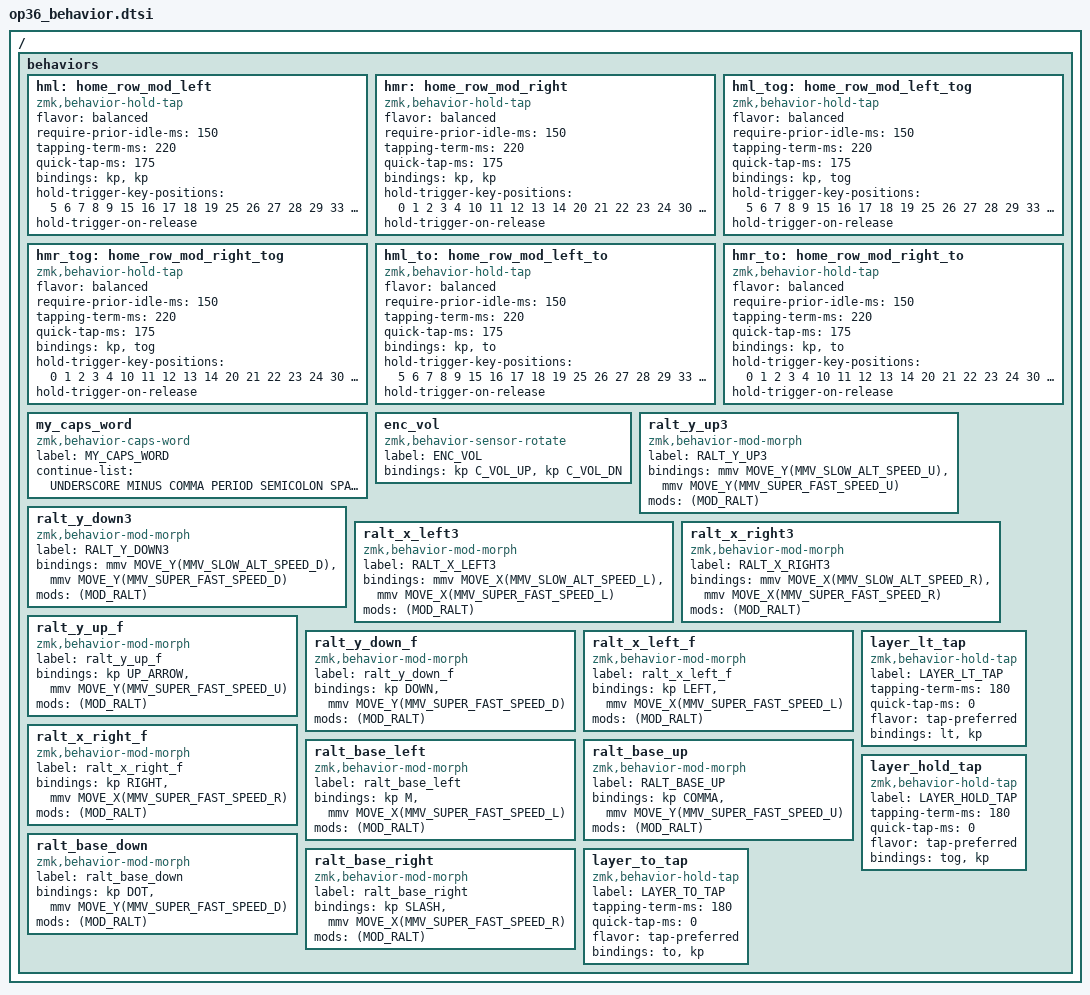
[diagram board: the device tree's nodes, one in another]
// op36_behavior.dtsi

#include "op36_const.dtsi"

/ {
    behaviors {
        hml: home_row_mod_left {
            compatible = "zmk,behavior-hold-tap";
            #binding-cells = <2>;
            flavor = "balanced";
            require-prior-idle-ms = <150>;
            tapping-term-ms = <220>;
            quick-tap-ms = <175>;
            bindings = <&kp>, <&kp>;

            hold-trigger-key-positions = <5 6 7 8 9 15 16 17 18 19 25 26 27 28 29 33 34 35>;
            hold-trigger-on-release;
        };

        hmr: home_row_mod_right {
            compatible = "zmk,behavior-hold-tap";
            #binding-cells = <2>;
            flavor = "balanced";
            require-prior-idle-ms = <150>;
            tapping-term-ms = <220>;
            quick-tap-ms = <175>;
            bindings = <&kp>, <&kp>;

            hold-trigger-key-positions = <0 1 2 3 4 10 11 12 13 14 20 21 22 23 24 30 31 32>;
            hold-trigger-on-release;
        };
        
hml_tog: home_row_mod_left_tog {
            compatible = "zmk,behavior-hold-tap";
            #binding-cells = <2>;
            flavor = "balanced";
            require-prior-idle-ms = <150>;
            tapping-term-ms = <220>;
            quick-tap-ms = <175>;
            bindings = <&kp>, <&tog>;

            hold-trigger-key-positions = <5 6 7 8 9 15 16 17 18 19 25 26 27 28 29 33 34 35>;
            hold-trigger-on-release;
        };

        hmr_tog: home_row_mod_right_tog {
            compatible = "zmk,behavior-hold-tap";
            #binding-cells = <2>;
            flavor = "balanced";
            require-prior-idle-ms = <150>;
            tapping-term-ms = <220>;
            quick-tap-ms = <175>;
            bindings = <&kp>, <&tog>;

            hold-trigger-key-positions = <0 1 2 3 4 10 11 12 13 14 20 21 22 23 24 30 31 32>;
            hold-trigger-on-release;
        };
        
        hml_to: home_row_mod_left_to {
                    compatible = "zmk,behavior-hold-tap";
                    #binding-cells = <2>;
                    flavor = "balanced";
                    require-prior-idle-ms = <150>;
                    tapping-term-ms = <220>;
                    quick-tap-ms = <175>;
                    bindings = <&kp>, <&to>;
        
                    hold-trigger-key-positions = <5 6 7 8 9 15 16 17 18 19 25 26 27 28 29 33 34 35>;
                    hold-trigger-on-release;
                };
        
                hmr_to: home_row_mod_right_to {
                    compatible = "zmk,behavior-hold-tap";
                    #binding-cells = <2>;
                    flavor = "balanced";
                    require-prior-idle-ms = <150>;
                    tapping-term-ms = <220>;
                    quick-tap-ms = <175>;
                    bindings = <&kp>, <&to>;
        
                    hold-trigger-key-positions = <0 1 2 3 4 10 11 12 13 14 20 21 22 23 24 30 31 32>;
                    hold-trigger-on-release;
                };                
        
         my_caps_word: my_caps_word {
             compatible = "zmk,behavior-caps-word";
             label = "MY_CAPS_WORD";
             #binding-cells = <0>;
             continue-list = <UNDERSCORE MINUS COMMA PERIOD SEMICOLON SPACE SLASH BACKSLASH>;
         };
                    
            enc_vol: enc_vol {
              compatible = "zmk,behavior-sensor-rotate";
              label = "ENC_VOL";
              #sensor-binding-cells = <0>;
              bindings = <&kp C_VOL_UP>, <&kp C_VOL_DN>;
            };
            
            ralt_y_up3: ralt_y_up3 {
              compatible = "zmk,behavior-mod-morph";
              label = "RALT_Y_UP3";
              #binding-cells = <0>;
              bindings = 
                <&mmv MOVE_Y(MMV_SLOW_ALT_SPEED_U)>,
                <&mmv MOVE_Y(MMV_SUPER_FAST_SPEED_U)>;
              mods = <(MOD_RALT)>;
            };
        
            ralt_y_down3: ralt_y_down3 {
              compatible = "zmk,behavior-mod-morph";
              label = "RALT_Y_DOWN3";
              #binding-cells = <0>;
              bindings = 
                <&mmv MOVE_Y(MMV_SLOW_ALT_SPEED_D)>,
                <&mmv MOVE_Y(MMV_SUPER_FAST_SPEED_D)>;
              mods = <(MOD_RALT)>;
            };
        
            ralt_x_left3: ralt_x_left3 {
              compatible = "zmk,behavior-mod-morph";
              label = "RALT_X_LEFT3";
              #binding-cells = <0>;
              bindings =
                <&mmv MOVE_X(MMV_SLOW_ALT_SPEED_L)>,
                <&mmv MOVE_X(MMV_SUPER_FAST_SPEED_L)>;
              mods = <(MOD_RALT)>;
            };
        
            ralt_x_right3: ralt_x_right3 {
              compatible = "zmk,behavior-mod-morph";
              label = "RALT_X_RIGHT3";
              #binding-cells = <0>;
              bindings =
                <&mmv MOVE_X(MMV_SLOW_ALT_SPEED_R)>,
                <&mmv MOVE_X(MMV_SUPER_FAST_SPEED_R)>;
              mods = <(MOD_RALT)>;
            };
            
            /* */
            ralt_y_up_f: ralt_y_up_f {
                  compatible = "zmk,behavior-mod-morph";
                  label = "ralt_y_up_f";
                  #binding-cells = <0>;
                  bindings = 
                    <&kp UP_ARROW>,
                    <&mmv MOVE_Y(MMV_SUPER_FAST_SPEED_U)>;
                  mods = <(MOD_RALT)>;
                };
            
                ralt_y_down_f: ralt_y_down_f {
                  compatible = "zmk,behavior-mod-morph";
                  label = "ralt_y_down_f";
                  #binding-cells = <0>;
                  bindings = 
                    <&kp DOWN>,
                    <&mmv MOVE_Y(MMV_SUPER_FAST_SPEED_D)>;
                  mods = <(MOD_RALT)>;
                };
            
                ralt_x_left_f: ralt_x_left_f {
                  compatible = "zmk,behavior-mod-morph";
                  label = "ralt_x_left_f";
                  #binding-cells = <0>;
                  bindings =
                    <&kp LEFT>,
                    <&mmv MOVE_X(MMV_SUPER_FAST_SPEED_L)>;
                  mods = <(MOD_RALT)>;
                };
            
                ralt_x_right_f: ralt_x_right_f {
                  compatible = "zmk,behavior-mod-morph";
                  label = "ralt_x_right_f";
                  #binding-cells = <0>;
                  bindings =
                    <&kp RIGHT>,
                    <&mmv MOVE_X(MMV_SUPER_FAST_SPEED_R)>;
                  mods = <(MOD_RALT)>;
                };
            /* */
        
            /* mouse 0 layer */
            ralt_base_left: ralt_base_left {
              compatible = "zmk,behavior-mod-morph";
              label = "ralt_base_left";
              #binding-cells = <0>;
              bindings =
                <&kp M>,
                <&mmv MOVE_X(MMV_SUPER_FAST_SPEED_L)>;
              mods = <(MOD_RALT)>;
            };
        
            ralt_base_up: ralt_base_up {
              compatible = "zmk,behavior-mod-morph";
              label = "RALT_BASE_UP";
              #binding-cells = <0>;
              bindings = 
                <&kp COMMA>,
                <&mmv MOVE_Y(MMV_SUPER_FAST_SPEED_U)>;
              mods = <(MOD_RALT)>;
            };
        
            ralt_base_down: ralt_base_down {
              compatible = "zmk,behavior-mod-morph";
              label = "ralt_base_down";
              #binding-cells = <0>;
              bindings = 
                <&kp DOT>,
                <&mmv MOVE_Y(MMV_SUPER_FAST_SPEED_D)>;
              mods = <(MOD_RALT)>;
            };
        
            ralt_base_right: ralt_base_right {
              compatible = "zmk,behavior-mod-morph";
              label = "ralt_base_right";
              #binding-cells = <0>;
              bindings =
                <&kp SLASH>,
                <&mmv MOVE_X(MMV_SUPER_FAST_SPEED_R)>;
              mods = <(MOD_RALT)>;
            };
            /* end mouse 0 layer */
        
            layer_lt_tap: layer_lt_tap {
              compatible = "zmk,behavior-hold-tap";
              label = "LAYER_LT_TAP";
              #binding-cells = <2>;
              tapping-term-ms = <180>;
              quick-tap-ms = <0>;
              flavor = "tap-preferred";
              bindings = <&lt>, <&kp>;
            };
        
            layer_hold_tap: layer_hold_tap {
              compatible = "zmk,behavior-hold-tap";
              label = "LAYER_HOLD_TAP";
              #binding-cells = <2>;
              tapping-term-ms = <180>;
              quick-tap-ms = <0>;
              flavor = "tap-preferred";
              bindings = <&tog>, <&kp>;
            };
            
            layer_to_tap: layer_to_tap {
              compatible = "zmk,behavior-hold-tap";
              label = "LAYER_TO_TAP";
              #binding-cells = <2>;
              tapping-term-ms = <180>;
              quick-tap-ms = <0>;
              flavor = "tap-preferred";
              bindings = <&to>, <&kp>;
            };
    };
};    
